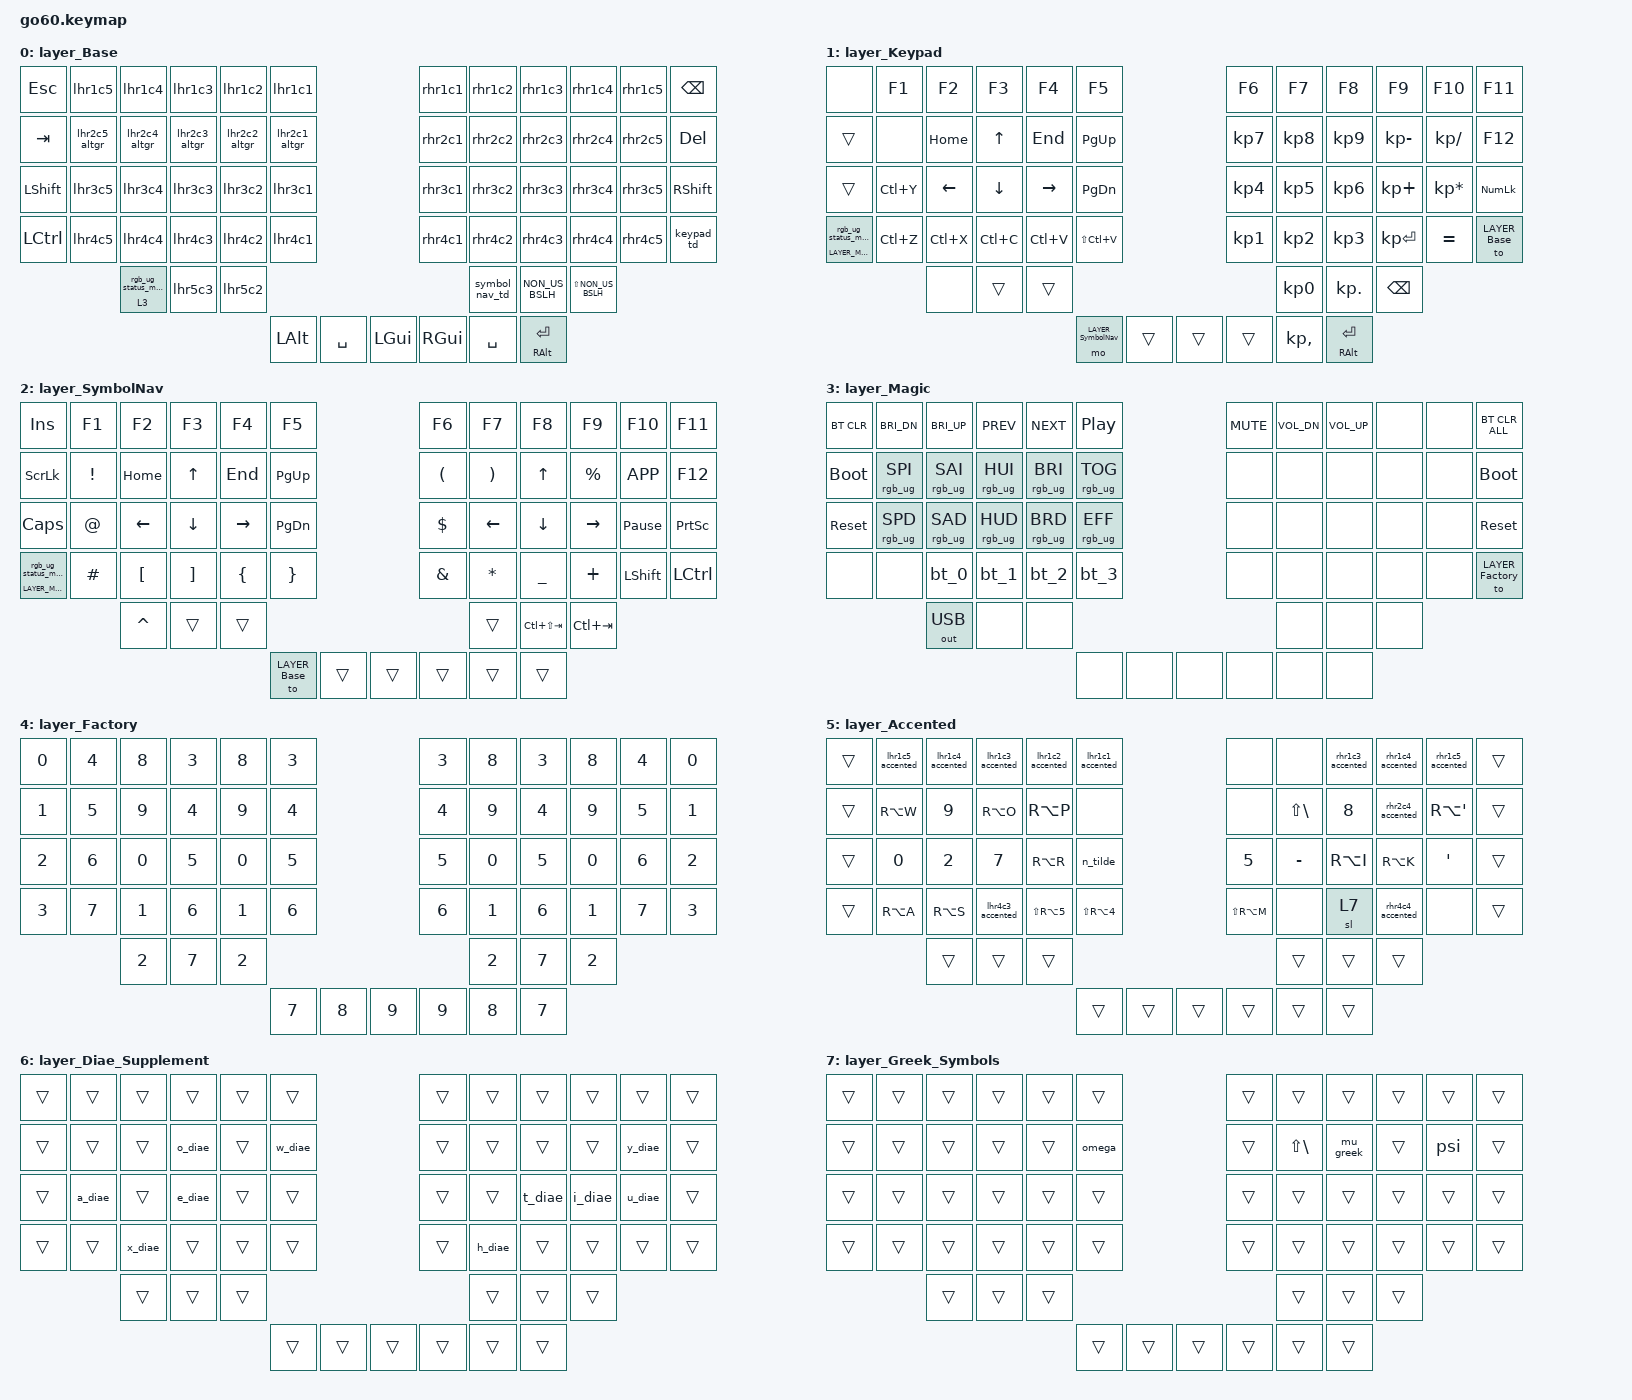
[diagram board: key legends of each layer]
/*
 * Copyright (c) 2020 The ZMK Contributors
 *
 * SPDX-License-Identifier: MIT
 */

#include <dt-bindings/zmk/input_transform.h>
#include <input/processors.dtsi>
#include <zephyr/dt-bindings/input/input-event-codes.h>
#include <behaviors.dtsi>
#include <dt-bindings/zmk/bt.h>
#include <dt-bindings/zmk/keys.h>
#include <dt-bindings/zmk/outputs.h>
#include <dt-bindings/zmk/rgb.h>

// layers

#define LAYER_Base 0
#define LAYER_Keypad 1
#define LAYER_SymbolNav 2
#define LAYER_Magic 3
#define LAYER_Factory 4

/ {
    input_processors {
        zip_click_to_right_click_mapper: zip_click_to_right_click_mapper {
            compatible = "zmk,input-processor-code-mapper";
            #input-processor-cells = <0>;
            type = <INPUT_EV_KEY>;
            map = <INPUT_BTN_0 INPUT_BTN_1>;
        };
    };

    behaviors {
        magic: magic {
            compatible = "zmk,behavior-hold-tap";
            #binding-cells = <2>;
            flavor = "tap-preferred";
            tapping-term-ms = <200>;
            bindings = <&mo>, <&rgb_ug_status_macro>;
        };

        keypad_td: keypad_td {
            compatible = "zmk,behavior-tap-dance";
            #binding-cells = <0>;
            tapping-term-ms = <200>;
            bindings = <&mo LAYER_Keypad>, <&to LAYER_Keypad>;
        };

        symbol_nav_td: symbol_nav_td {
            compatible = "zmk,behavior-tap-dance";
            #binding-cells = <0>;
            tapping-term-ms = <200>;
            bindings = <&mo LAYER_SymbolNav>, <&to LAYER_SymbolNav>;
        };

        bt_0: bt_0 {
            compatible = "zmk,behavior-tap-dance";
            #binding-cells = <0>;
            tapping-term-ms = <200>;
            bindings = <&bt_select_0>, <&bt BT_DISC 0>;
        };

        bt_1: bt_1 {
            compatible = "zmk,behavior-tap-dance";
            #binding-cells = <0>;
            tapping-term-ms = <200>;
            bindings = <&bt_select_1>, <&bt BT_DISC 1>;
        };

        bt_2: bt_2 {
            compatible = "zmk,behavior-tap-dance";
            #binding-cells = <0>;
            tapping-term-ms = <200>;
            bindings = <&bt_select_2>, <&bt BT_DISC 2>;
        };

        bt_3: bt_3 {
            compatible = "zmk,behavior-tap-dance";
            #binding-cells = <0>;
            tapping-term-ms = <200>;
            bindings = <&bt_select_3>, <&bt BT_DISC 3>;
        };


        /* ========================================================= *
         * MOD-MORPHS pour LH et RH R1 (touches 1-2-3-4-5-6-7-8-9-0) *
         * ========================================================= */

        /* =========
         * LH R1 C1 : 5 / % / ₅ / ⁵
         * ========= */

        lhr1c1_shift: lhr1c1_shift {
            compatible = "zmk,behavior-mod-morph";
            #binding-cells = <0>;
            mods = <(MOD_LSFT|MOD_RSFT)>;
            bindings = <&kp KP_N5 &kp LS(SQT)>;
        };

        lhr1c1_altgr_shift: lhr1c1_altgr_shift {
            compatible = "zmk,behavior-mod-morph";
            #binding-cells = <0>;
            mods = <(MOD_LSFT|MOD_RSFT)>;
            bindings = <&sub_5 &sup_5>;
        };

        lhr1c1: lhr1c1 {
            compatible = "zmk,behavior-mod-morph";
            #binding-cells = <0>;
            mods = <(MOD_RALT)>;
            bindings = <&lhr1c1_shift &lhr1c1_altgr_shift>;
        };

        /* =========
         * LH R1 C2 : 4 / $ / ₄ / ⁴
         * ========= */

        lhr1c2_shift: lhr1c2_shift {
            compatible = "zmk,behavior-mod-morph";
            #binding-cells = <0>;
            mods = <(MOD_LSFT|MOD_RSFT)>;
            bindings = <&kp KP_N4 &kp RBKT>;
        };

        lhr1c2_altgr_shift: lhr1c2_altgr_shift {
            compatible = "zmk,behavior-mod-morph";
            #binding-cells = <0>;
            mods = <(MOD_LSFT|MOD_RSFT)>;
            bindings = <&sub_4 &sup_4>;
        };

        lhr1c2: lhr1c2 {
            compatible = "zmk,behavior-mod-morph";
            #binding-cells = <0>;
            mods = <(MOD_RALT)>;
            bindings = <&lhr1c2_shift &lhr1c2_altgr_shift>;
        };

        /* =========
         * LH R1 C3 : 3 / » / ₃ / ³
         * ========= */

        lhr1c3_shift: lhr1c3_shift {
            compatible = "zmk,behavior-mod-morph";
            #binding-cells = <0>;
            mods = <(MOD_LSFT|MOD_RSFT)>;
            bindings = <&kp KP_N3 &kp RA(X)>;
        };

        lhr1c3_altgr_shift: lhr1c3_altgr_shift {
            compatible = "zmk,behavior-mod-morph";
            #binding-cells = <0>;
            mods = <(MOD_LSFT|MOD_RSFT)>;
            bindings = <&sub_3 &sup_3>;
        };

        lhr1c3: lhr1c3 {
            compatible = "zmk,behavior-mod-morph";
            #binding-cells = <0>;
            mods = <(MOD_RALT)>;
            bindings = <&lhr1c3_shift &lhr1c3_altgr_shift>;
        };

        /* =========
         * LH R1 C4 : 2 / « / ₂ / ²
         * ========= */

        lhr1c4_shift: lhr1c4_shift {
            compatible = "zmk,behavior-mod-morph";
            #binding-cells = <0>;
            mods = <(MOD_LSFT|MOD_RSFT)>;
            bindings = <&kp KP_N2 &kp RA(Z)>;
        };

        lhr1c4_altgr_shift: lhr1c4_altgr_shift {
            compatible = "zmk,behavior-mod-morph";
            #binding-cells = <0>;
            mods = <(MOD_LSFT|MOD_RSFT)>;
            bindings = <&sub_2 &sup_2>;
        };

        lhr1c4: lhr1c4 {
            compatible = "zmk,behavior-mod-morph";
            #binding-cells = <0>;
            mods = <(MOD_RALT)>;
            bindings = <&lhr1c4_shift &lhr1c4_altgr_shift>;
        };

        /* =========
         * LH R1 C5 : 1 / € / ₁ / ¹
         * ========= */

        lhr1c5_shift: lhr1c5_shift {
            compatible = "zmk,behavior-mod-morph";
            #binding-cells = <0>;
            mods = <(MOD_LSFT|MOD_RSFT)>;
            bindings = <&kp KP_N1 &kp RA(E)>;
        };

        lhr1c5_altgr_shift: lhr1c5_altgr_shift {
            compatible = "zmk,behavior-mod-morph";
            #binding-cells = <0>;
            mods = <(MOD_LSFT|MOD_RSFT)>;
            bindings = <&sub_1 &sup_1>;
        };

        lhr1c5: lhr1c5 {
            compatible = "zmk,behavior-mod-morph";
            #binding-cells = <0>;
            mods = <(MOD_RALT)>;
            bindings = <&lhr1c5_shift &lhr1c5_altgr_shift>;
        };

        /* =========
         * RH R1 C1 : 6 / ^ / ₆ / ⁶
         * ========= */
        
        rhr1c1_shift: rhr1c1_shift {
            compatible = "zmk,behavior-mod-morph";
            #binding-cells = <0>;
            mods = <(MOD_LSFT|MOD_RSFT)>;
            bindings = <&kp KP_N6 &kp LBKT>;       // ^ = LBKT en FR
        };
        
        rhr1c1_altgr_shift: rhr1c1_altgr_shift {
            compatible = "zmk,behavior-mod-morph";
            #binding-cells = <0>;
            mods = <(MOD_LSFT|MOD_RSFT)>;
            bindings = <&sub_6 &sup_6>;
        };
        
        rhr1c1: rhr1c1 {
            compatible = "zmk,behavior-mod-morph";
            #binding-cells = <0>;
            mods = <(MOD_RALT)>;
            bindings = <&rhr1c1_shift &rhr1c1_altgr_shift>;
        };
        
        /* =========
         * RH R1 C2 : 7 / & / ₇ / ⁷
         * ========= */
        
        rhr1c2_shift: rhr1c2_shift {
            compatible = "zmk,behavior-mod-morph";
            #binding-cells = <0>;
            mods = <(MOD_LSFT|MOD_RSFT)>;
            bindings = <&kp KP_N7 &kp N1>;         // & = N1 en FR
        };
        
        rhr1c2_altgr_shift: rhr1c2_altgr_shift {
            compatible = "zmk,behavior-mod-morph";
            #binding-cells = <0>;
            mods = <(MOD_LSFT|MOD_RSFT)>;
            bindings = <&sub_7 &sup_7>;
        };
        
        rhr1c2: rhr1c2 {
            compatible = "zmk,behavior-mod-morph";
            #binding-cells = <0>;
            mods = <(MOD_RALT)>;
            bindings = <&rhr1c2_shift &rhr1c2_altgr_shift>;
        };
        
        /* =========
         * RH R1 C3 : 8 / * / ₈ / ⁸
         * ========= */
        
        rhr1c3_shift: rhr1c3_shift {
            compatible = "zmk,behavior-mod-morph";
            #binding-cells = <0>;
            mods = <(MOD_LSFT|MOD_RSFT)>;
            bindings = <&kp KP_N8 &kp BSLH>;       // * = BSLH en FR
        };
        
        rhr1c3_altgr_shift: rhr1c3_altgr_shift {
            compatible = "zmk,behavior-mod-morph";
            #binding-cells = <0>;
            mods = <(MOD_LSFT|MOD_RSFT)>;
            bindings = <&sub_8 &sup_8>;
        };
        
        rhr1c3: rhr1c3 {
            compatible = "zmk,behavior-mod-morph";
            #binding-cells = <0>;
            mods = <(MOD_RALT)>;
            bindings = <&rhr1c3_shift &rhr1c3_altgr_shift>;
        };
        
        /* =========
         * RH R1 C4 : 9 / # / ₉ / ⁹
         * ========= */
        
        rhr1c4_shift: rhr1c4_shift {
            compatible = "zmk,behavior-mod-morph";
            #binding-cells = <0>;
            mods = <(MOD_LSFT|MOD_RSFT)>;
            bindings = <&kp KP_N9 &kp RA(N3)>;     // # = AltGr+3 en FR
        };
        
        rhr1c4_altgr_shift: rhr1c4_altgr_shift {
            compatible = "zmk,behavior-mod-morph";
            #binding-cells = <0>;
            mods = <(MOD_LSFT|MOD_RSFT)>;
            bindings = <&sub_9 &sup_9>;
        };
        
        rhr1c4: rhr1c4 {
            compatible = "zmk,behavior-mod-morph";
            #binding-cells = <0>;
            mods = <(MOD_RALT)>;
            bindings = <&rhr1c4_shift &rhr1c4_altgr_shift>;
        };
        
        /* =========
         * RH R1 C5 : 0 / @ / ₀ / ⁰
         * ========= */
        
        rhr1c5_shift: rhr1c5_shift {
            compatible = "zmk,behavior-mod-morph";
            #binding-cells = <0>;
            mods = <(MOD_LSFT|MOD_RSFT)>;
            bindings = <&kp KP_N0 &kp RA(N0)>;     // @ = AltGr+0 en FR
        };
        
        rhr1c5_altgr_shift: rhr1c5_altgr_shift {
            compatible = "zmk,behavior-mod-morph";
            #binding-cells = <0>;
            mods = <(MOD_LSFT|MOD_RSFT)>;
            bindings = <&sub_0 &sup_0>;
        };
        
        rhr1c5: rhr1c5 {
            compatible = "zmk,behavior-mod-morph";
            #binding-cells = <0>;
            mods = <(MOD_RALT)>;
            bindings = <&rhr1c5_shift &rhr1c5_altgr_shift>;
        };

        /* ========================================================= *
         * MOD-MORPHS pour LH et RH R2 (touches q-c-o-p-w-j-m-d-*-y) *
         * ========================================================= */

        /* =========
         * LH R2 C5 : q / Q / ^ / none
         * ========= */
        
        // NIVEAU 1 : Détecte AltGr
        lhr2c5_altgr: lhr2c5_altgr {
            compatible = "zmk,behavior-mod-morph";
            #binding-cells = <0>;
            mods = <(MOD_RALT)>;
            bindings = <&kp A &lhr2c5_shift_altgr>;
        };
        
        // NIVEAU 2 : Avec AltGr (détecte Shift)
        lhr2c5_shift_altgr: lhr2c5_shift_altgr {
            compatible = "zmk,behavior-mod-morph";
            #binding-cells = <0>;
            mods = <(MOD_LSFT|MOD_RSFT)>;
            bindings = <&kp RA(N9) &none>;    // AltGr = ^, Shift+AltGr = RIEN
        };

        /* =========
         * LH R2 C4 : c / C / < / ≤
         * ========= */

        lhr2c4_altgr_shift: lhr2c4_altgr_shift {
            compatible = "zmk,behavior-mod-morph";
            #binding-cells = <0>;
            mods = <(MOD_LSFT|MOD_RSFT)>;
            bindings = <&kp NON_US_BSLH &kp RA(NON_US_BSLH)>;
        };

        lhr2c4_altgr: lhr2c4_altgr {
            compatible = "zmk,behavior-mod-morph";
            #binding-cells = <0>;
            mods = <(MOD_RALT)>;
            bindings = <&kp C &lhr2c4_altgr_shift>;
        };

        /* =========
         * LH R2 C3 : o / O / > / ≥
         * ========= */

        lhr2c3_altgr_shift: lhr2c3_altgr_shift {
            compatible = "zmk,behavior-mod-morph";
            #binding-cells = <0>;
            mods = <(MOD_LSFT|MOD_RSFT)>;
            bindings = <&kp LS(NON_US_BSLH) &kp LS(RA(NON_US_BSLH))>;
        };

        lhr2c3_altgr: lhr2c3_altgr {
            compatible = "zmk,behavior-mod-morph";
            #binding-cells = <0>;
            mods = <(MOD_RALT)>;
            bindings = <&kp O &lhr2c3_altgr_shift>;
        };

        /* =========
         * LH R2 C2 : p / P / $ / none
         * ========= */

        lhr2c2_altgr: lhr2c2_altgr {
            compatible = "zmk,behavior-mod-morph";
            #binding-cells = <0>;
            mods = <(MOD_RALT)>;
            bindings = <&kp P &lhr2c2_shift_altgr>;
        };

        lhr2c2_shift_altgr: lhr2c2_shift_altgr {
            compatible = "zmk,behavior-mod-morph";
            #binding-cells = <0>;
            mods = <(MOD_LSFT|MOD_RSFT)>;
            bindings = <&kp RBKT  &none>;    // AltGr = $, Shift+AltGr = RIEN
        };
    
        /* =========
         * LH R2 C1 : w / W / % / ‰
         * ========= */

        lhr2c1_altgr: lhr2c1_altgr {
            compatible = "zmk,behavior-mod-morph";
            #binding-cells = <0>;
            mods = <(MOD_RALT)>;
            bindings = <&kp Z &lhr2c1_altgr_shift>;
        };

        lhr2c1_altgr_shift: lhr2c1_altgr_shift {
            compatible = "zmk,behavior-mod-morph";
            #binding-cells = <0>;
            mods = <(MOD_LSFT|MOD_RSFT)>;
            bindings = <&kp LS(SQT) &permille_compose>;
        };

        /* =========
         * RH R2 C1 : j / J / @ / rien
         * ========= */
        
        rhr2c1: rhr2c1 {
            compatible = "zmk,behavior-mod-morph";
            #binding-cells = <0>;
            mods = <(MOD_RALT)>;
            bindings = <&kp J &rhr2c1_shift_altgr>;
        };
        
        rhr2c1_shift_altgr: rhr2c1_shift_altgr {
            compatible = "zmk,behavior-mod-morph";
            #binding-cells = <0>;
            mods = <(MOD_LSFT|MOD_RSFT)>;
            bindings = <&kp RA(N0) &none>;       // @ = AltGr+0 en FR, Shift+AltGr = rien
        };
        
        /* =========
         * RH R2 C2 : m / M / & / rien
         * ========= */
        
        rhr2c2: rhr2c2 {
            compatible = "zmk,behavior-mod-morph";
            #binding-cells = <0>;
            mods = <(MOD_RALT)>;
            bindings = <&kp SEMICOLON &rhr2c2_shift_altgr>;  // M en mapping inversé = SEMICOLON
        };
        
        rhr2c2_shift_altgr: rhr2c2_shift_altgr {
            compatible = "zmk,behavior-mod-morph";
            #binding-cells = <0>;
            mods = <(MOD_LSFT|MOD_RSFT)>;
            bindings = <&kp N1 &none>;           // & = N1 en FR, Shift+AltGr = rien
        };
        
        /* =========
         * RH R2 C3 : d / D / * / ×
         * ========= */
        
        rhr2c3: rhr2c3 {
            compatible = "zmk,behavior-mod-morph";
            #binding-cells = <0>;
            mods = <(MOD_RALT)>;
            bindings = <&kp D &rhr2c3_shift_altgr>;
        };
        
        rhr2c3_shift_altgr: rhr2c3_shift_altgr {
            compatible = "zmk,behavior-mod-morph";
            #binding-cells = <0>;
            mods = <(MOD_LSFT|MOD_RSFT)>;
            bindings = <&kp BSLH &kp RA(COMMA)>;  // * = BSLH, × = AltGr+; (COMMA en FR)
        };
        
        /* =========
         * RH R2 C4 : layer_accented / ! / ' / rien
         * ========= */
        
        rhr2c4: rhr2c4 {
            compatible = "zmk,behavior-mod-morph";
            #binding-cells = <0>;
            mods = <(MOD_RALT)>;
            bindings = <&rhr2c4_no_altgr &rhr2c4_shift_altgr>;
        };
        
        rhr2c4_no_altgr: rhr2c4_no_altgr {
            compatible = "zmk,behavior-mod-morph";
            #binding-cells = <0>;
            mods = <(MOD_LSFT|MOD_RSFT)>;
            bindings = <&sl 5 &kp FSLH>;   // layer accents / ! (Shift+SLASH en FR)
        };
        
        rhr2c4_shift_altgr: rhr2c4_shift_altgr {
            compatible = "zmk,behavior-mod-morph";
            #binding-cells = <0>;
            mods = <(MOD_LSFT|MOD_RSFT)>;
            bindings = <&kp N4 &none>;              // ' = N4 en FR, Shift+AltGr = rien
        };
        
        /* =========
         * RH R2 C5 : y / Y / ` / rien
         * ========= */
        
        rhr2c5: rhr2c5 {
            compatible = "zmk,behavior-mod-morph";
            #binding-cells = <0>;
            mods = <(MOD_RALT)>;
            bindings = <&kp Y &rhr2c5_shift_altgr>;
        };
        
        rhr2c5_shift_altgr: rhr2c5_shift_altgr {
            compatible = "zmk,behavior-mod-morph";
            #binding-cells = <0>;
            mods = <(MOD_LSFT|MOD_RSFT)>;
            bindings = <&kp RA(N7) &none>;            // ` = AltGr+7 en FR, Shift+AltGr = rien
        };


        /* ========================================================= *
         * MOD-MORPHS pour LH et RH R3 (touches a-s-e-n-f-l-r-t-i-u  *
         * ========================================================= */

        /* ==========================================
         * MOD-MORPHS pour LH R3
         * ========================================== */
        
        /* =========
         * LH R3 C1 : f / F / = / ≠
         * ========= */
        
        lhr3c1: lhr3c1 {
            compatible = "zmk,behavior-mod-morph";
            #binding-cells = <0>;
            mods = <(MOD_RALT)>;
            bindings = <&kp F &lhr3c1_shift_altgr>;
        };
        
        lhr3c1_shift_altgr: lhr3c1_shift_altgr {
            compatible = "zmk,behavior-mod-morph";
            #binding-cells = <0>;
            mods = <(MOD_LSFT|MOD_RSFT)>;
            bindings = <&kp EQUAL &kp LS(RA(MINUS))>;   // = / ≠
        };
        
        /* =========
         * LH R3 C2 : n / N / } / rien
         * ========= */
        
        lhr3c2: lhr3c2 {
            compatible = "zmk,behavior-mod-morph";
            #binding-cells = <0>;
            mods = <(MOD_RALT)>;
            bindings = <&kp N &lhr3c2_shift_altgr>;
        };
        
        lhr3c2_shift_altgr: lhr3c2_shift_altgr {
            compatible = "zmk,behavior-mod-morph";
            #binding-cells = <0>;
            mods = <(MOD_LSFT|MOD_RSFT)>;
            bindings = <&kp RA(EQUAL) &none>;           // } / rien
        };
        
        /* =========
         * LH R3 C3 : e / E / ) / rien
         * ========= */
        
        lhr3c3: lhr3c3 {
            compatible = "zmk,behavior-mod-morph";
            #binding-cells = <0>;
            mods = <(MOD_RALT)>;
            bindings = <&kp E &lhr3c3_shift_altgr>;
        };
        
        lhr3c3_shift_altgr: lhr3c3_shift_altgr {
            compatible = "zmk,behavior-mod-morph";
            #binding-cells = <0>;
            mods = <(MOD_LSFT|MOD_RSFT)>;
            bindings = <&kp MINUS &none>;               // ) / rien
        };
        
        /* =========
         * LH R3 C4 : s / S / ( / rien
         * ========= */
        
        lhr3c4: lhr3c4 {
            compatible = "zmk,behavior-mod-morph";
            #binding-cells = <0>;
            mods = <(MOD_RALT)>;
            bindings = <&kp S &lhr3c4_shift_altgr>;
        };
        
        lhr3c4_shift_altgr: lhr3c4_shift_altgr {
            compatible = "zmk,behavior-mod-morph";
            #binding-cells = <0>;
            mods = <(MOD_LSFT|MOD_RSFT)>;
            bindings = <&kp N5 &none>;                  // ( / rien
        };
        
        /* =========
         * LH R3 C5 : a / A / { / rien
         * ========= */
        
        lhr3c5: lhr3c5 {
            compatible = "zmk,behavior-mod-morph";
            #binding-cells = <0>;
            mods = <(MOD_RALT)>;
            bindings = <&kp Q &lhr3c5_shift_altgr>;     // A en mapping inversé = Q
        };
        
        lhr3c5_shift_altgr: lhr3c5_shift_altgr {
            compatible = "zmk,behavior-mod-morph";
            #binding-cells = <0>;
            mods = <(MOD_LSFT|MOD_RSFT)>;
            bindings = <&kp RA(N4) &none>;              // { / rien
        };
        
        /* ==========================================
         * MOD-MORPHS pour RH R3
         * ========================================== */
        
        /* =========
         * RH R3 C1 : l / L / \ / rien
         * ========= */
        
        rhr3c1: rhr3c1 {
            compatible = "zmk,behavior-mod-morph";
            #binding-cells = <0>;
            mods = <(MOD_RALT)>;
            bindings = <&kp L &rhr3c1_shift_altgr>;
        };
        
        rhr3c1_shift_altgr: rhr3c1_shift_altgr {
            compatible = "zmk,behavior-mod-morph";
            #binding-cells = <0>;
            mods = <(MOD_LSFT|MOD_RSFT)>;
            bindings = <&kp RA(N8) &none>;              // \ / rien
        };
        
        /* =========
         * RH R3 C2 : r / R / + / ±
         * ========= */
        
        rhr3c2: rhr3c2 {
            compatible = "zmk,behavior-mod-morph";
            #binding-cells = <0>;
            mods = <(MOD_RALT)>;
            bindings = <&kp R &rhr3c2_shift_altgr>;
        };
        
        rhr3c2_shift_altgr: rhr3c2_shift_altgr {
            compatible = "zmk,behavior-mod-morph";
            #binding-cells = <0>;
            mods = <(MOD_LSFT|MOD_RSFT)>;
            bindings = <&kp LS(EQUAL) &kp LS(RA(EQUAL))>;  // + / ±
        };
        
        /* =========
         * RH R3 C3 : t / T / - / rien
         * ========= */
        
        rhr3c3: rhr3c3 {
            compatible = "zmk,behavior-mod-morph";
            #binding-cells = <0>;
            mods = <(MOD_RALT)>;
            bindings = <&kp T &rhr3c3_shift_altgr>;
        };
        
        rhr3c3_shift_altgr: rhr3c3_shift_altgr {
            compatible = "zmk,behavior-mod-morph";
            #binding-cells = <0>;
            mods = <(MOD_LSFT|MOD_RSFT)>;
            bindings = <&kp N6 &none>;                  // - / rien
        };
        
        /* =========
         * RH R3 C4 : i / I / / / ÷
         * ========= */
        
        rhr3c4: rhr3c4 {
            compatible = "zmk,behavior-mod-morph";
            #binding-cells = <0>;
            mods = <(MOD_RALT)>;
            bindings = <&kp I &rhr3c4_shift_altgr>;
        };
        
        rhr3c4_shift_altgr: rhr3c4_shift_altgr {
            compatible = "zmk,behavior-mod-morph";
            #binding-cells = <0>;
            mods = <(MOD_LSFT|MOD_RSFT)>;
            bindings = <&kp LS(DOT) &kp RA(DOT)>;       // / / ÷
        };
        
        /* =========
         * RH R3 C5 : u / U / " / rien
         * ========= */
        
        rhr3c5: rhr3c5 {
            compatible = "zmk,behavior-mod-morph";
            #binding-cells = <0>;
            mods = <(MOD_RALT)>;
            bindings = <&kp U &rhr3c5_shift_altgr>;
        };
        
        rhr3c5_shift_altgr: rhr3c5_shift_altgr {
            compatible = "zmk,behavior-mod-morph";
            #binding-cells = <0>;
            mods = <(MOD_LSFT|MOD_RSFT)>;
            bindings = <&kp N3 &none>;                  // " / rien
        };

        /* ========================================================= *
         * MOD-MORPHS pour LH et RH R4 (touches z-x---v-b-.-h-g-.-k  *
         * ========================================================= */
        
        /* ==========================================
         * MOD-MORPHS pour LH R4
         * ========================================== */
        
        /* =========
         * LH R4 C1 : b / B / # / rien
         * ========= */
        
        lhr4c1: lhr4c1 {
            compatible = "zmk,behavior-mod-morph";
            #binding-cells = <0>;
            mods = <(MOD_RALT)>;
            bindings = <&kp B &lhr4c1_shift_altgr>;
        };
        
        lhr4c1_shift_altgr: lhr4c1_shift_altgr {
            compatible = "zmk,behavior-mod-morph";
            #binding-cells = <0>;
            mods = <(MOD_LSFT|MOD_RSFT)>;
            bindings = <&kp RA(N3) &none>;             // # / rien
        };
        
        /* =========
         * LH R4 C2 : v / V / _ / –
         * ========= */
        
        lhr4c2: lhr4c2 {
            compatible = "zmk,behavior-mod-morph";
            #binding-cells = <0>;
            mods = <(MOD_RALT)>;
            bindings = <&kp V &lhr4c2_shift_altgr>;
        };
        
        lhr4c2_shift_altgr: lhr4c2_shift_altgr {
            compatible = "zmk,behavior-mod-morph";
            #binding-cells = <0>;
            mods = <(MOD_LSFT|MOD_RSFT)>;
            bindings = <&kp N8 &kp LS(RA(N5))>;        // _ / –
        };
        
        /* =========
         * LH R4 C3 : - / ? / ] / rien
         * ========= */
        
        lhr4c3: lhr4c3 {
            compatible = "zmk,behavior-mod-morph";
            #binding-cells = <0>;
            mods = <(MOD_RALT)>;
            bindings = <&lhr4c3_no_altgr &lhr4c3_shift_altgr>;
        };
        
        lhr4c3_no_altgr: lhr4c3_no_altgr {
            compatible = "zmk,behavior-mod-morph";
            #binding-cells = <0>;
            mods = <(MOD_LSFT|MOD_RSFT)>;
            bindings = <&kp N6 &kp LS(M)>;             // - / ?
        };
        
        lhr4c3_shift_altgr: lhr4c3_shift_altgr {
            compatible = "zmk,behavior-mod-morph";
            #binding-cells = <0>;
            mods = <(MOD_LSFT|MOD_RSFT)>;
            bindings = <&kp RA(MINUS) &none>;          // ] / rien
        };
        
        /* =========
         * LH R4 C4 : x / X / [ / rien
         * ========= */
        
        lhr4c4: lhr4c4 {
            compatible = "zmk,behavior-mod-morph";
            #binding-cells = <0>;
            mods = <(MOD_RALT)>;
            bindings = <&kp X &lhr4c4_shift_altgr>;
        };
        
        lhr4c4_shift_altgr: lhr4c4_shift_altgr {
            compatible = "zmk,behavior-mod-morph";
            #binding-cells = <0>;
            mods = <(MOD_LSFT|MOD_RSFT)>;
            bindings = <&kp RA(N5) &none>;             // [ / rien
        };
        
        /* =========
         * LH R4 C5 : z / Z / ~ / rien
         * ========= */
        
        lhr4c5: lhr4c5 {
            compatible = "zmk,behavior-mod-morph";
            #binding-cells = <0>;
            mods = <(MOD_RALT)>;
            bindings = <&kp W &lhr4c5_shift_altgr>;    // Z en mapping inversé = W
        };
        
        lhr4c5_shift_altgr: lhr4c5_shift_altgr {
            compatible = "zmk,behavior-mod-morph";
            #binding-cells = <0>;
            mods = <(MOD_LSFT|MOD_RSFT)>;
            bindings = <&kp RA(N2) &none>;             // ~ / rien
        };
        
        /* ==========================================
         * MOD-MORPHS pour RH R4
         * ========================================== */
        
        /* =========
         * RH R4 C1 : . / : / | / ¦
         * ========= */
        
        rhr4c1: rhr4c1 {
            compatible = "zmk,behavior-mod-morph";
            #binding-cells = <0>;
            mods = <(MOD_RALT)>;
            bindings = <&rhr4c1_no_altgr &rhr4c1_shift_altgr>;
        };
        
        rhr4c1_no_altgr: rhr4c1_no_altgr {
            compatible = "zmk,behavior-mod-morph";
            #binding-cells = <0>;
            mods = <(MOD_LSFT|MOD_RSFT)>;
            bindings = <&kp LS(COMMA) &kp DOT>;        // . / :
        };
        
        rhr4c1_shift_altgr: rhr4c1_shift_altgr {
            compatible = "zmk,behavior-mod-morph";
            #binding-cells = <0>;
            mods = <(MOD_LSFT|MOD_RSFT)>;
            bindings = <&kp RA(N6) &broken_bar_compose>;  // | / ¦
        };
        
        /* =========
         * RH R4 C2 : h / H / ! / ¬
         * ========= */
        
        rhr4c2: rhr4c2 {
            compatible = "zmk,behavior-mod-morph";
            #binding-cells = <0>;
            mods = <(MOD_RALT)>;
            bindings = <&kp H &rhr4c2_shift_altgr>;
        };
        
        rhr4c2_shift_altgr: rhr4c2_shift_altgr {
            compatible = "zmk,behavior-mod-morph";
            #binding-cells = <0>;
            mods = <(MOD_LSFT|MOD_RSFT)>;
            bindings = <&kp FSLH &kp RA(N)>;           // ! / ¬
        };
        
        /* =========
         * RH R4 C3 : g / G / ; / rien
         * ========= */
        
        rhr4c3: rhr4c3 {
            compatible = "zmk,behavior-mod-morph";
            #binding-cells = <0>;
            mods = <(MOD_RALT)>;
            bindings = <&kp G &rhr4c3_shift_altgr>;
        };
        
        rhr4c3_shift_altgr: rhr4c3_shift_altgr {
            compatible = "zmk,behavior-mod-morph";
            #binding-cells = <0>;
            mods = <(MOD_LSFT|MOD_RSFT)>;
            bindings = <&kp COMMA &none>;              // ; / rien
        };
        
        /* =========
         * RH R4 C4 : , / ; / : / rien
         * ========= */
        
        rhr4c4: rhr4c4 {
            compatible = "zmk,behavior-mod-morph";
            #binding-cells = <0>;
            mods = <(MOD_RALT)>;
            bindings = <&rhr4c4_no_altgr &rhr4c4_shift_altgr>;
        };
        
        rhr4c4_no_altgr: rhr4c4_no_altgr {
            compatible = "zmk,behavior-mod-morph";
            #binding-cells = <0>;
            mods = <(MOD_LSFT|MOD_RSFT)>;
            bindings = <&kp M &kp COMMA>;              // , / ;
        };
        
        rhr4c4_shift_altgr: rhr4c4_shift_altgr {
            compatible = "zmk,behavior-mod-morph";
            #binding-cells = <0>;
            mods = <(MOD_LSFT|MOD_RSFT)>;
            bindings = <&kp DOT &none>;                // : / rien
        };
        
        /* =========
         * RH R4 C5 : k / K / ? / rien
         * ========= */
        
        rhr4c5: rhr4c5 {
            compatible = "zmk,behavior-mod-morph";
            #binding-cells = <0>;
            mods = <(MOD_RALT)>;
            bindings = <&kp K &rhr4c5_shift_altgr>;
        };
        
        rhr4c5_shift_altgr: rhr4c5_shift_altgr {
            compatible = "zmk,behavior-mod-morph";
            #binding-cells = <0>;
            mods = <(MOD_LSFT|MOD_RSFT)>;
            bindings = <&kp LS(M) &none>;              // ? / rien
        };


        /* ========================================================= *
         * LH R5 C3 et C2 (parenthèses/crochets/acc) *
         * ========================================================= */

        /* =========
         * LH R5 C3 : ( / [ / {
         * ========= */

        lhr5c3: lhr5c3 {
            compatible = "zmk,behavior-mod-morph";
            #binding-cells = <0>;
            mods = <(MOD_RALT)>;
            bindings = <&lhr5c3_no_altgr &lhr5c3_altgr>;
        };

        lhr5c3_no_altgr: lhr5c3_no_altgr {
            compatible = "zmk,behavior-mod-morph";
            #binding-cells = <0>;
            mods = <(MOD_LSFT|MOD_RSFT)>;
            bindings = <&kp N5 &kp RA(N5)>;              // ( ou [
        };

        lhr5c3_altgr: lhr5c3_altgr {
            compatible = "zmk,behavior-mod-morph";
            #binding-cells = <0>;
            mods = <(MOD_LSFT|MOD_RSFT)>;
            bindings = <&kp RA(N4) &none>;          // { / {
        };


        /* =========
         * LH R5 C2 : ) / ] / }
         * ========= */

        lhr5c2: lhr5c2 {
            compatible = "zmk,behavior-mod-morph";
            #binding-cells = <0>;
            mods = <(MOD_RALT)>;
            bindings = <&lhr5c2_no_altgr &lhr5c2_altgr>;
        };

        lhr5c2_no_altgr: lhr5c2_no_altgr {
            compatible = "zmk,behavior-mod-morph";
            #binding-cells = <0>;
            mods = <(MOD_LSFT|MOD_RSFT)>;
            bindings = <&kp MINUS &kp RA(MINUS)>;        // ) / ]
        };

        lhr5c2_altgr: lhr5c2_altgr {
            compatible = "zmk,behavior-mod-morph";
            #binding-cells = <0>;
            mods = <(MOD_LSFT|MOD_RSFT)>;
            bindings = <&kp RA(EQUAL) &none>;    // } / }

        };

        /* ========================================================= *
         * je pense que les 5 fonctions suivantes sont inutiles                                     *
         * ========================================================= */

        minus_qmark: minus_qmark {
            compatible = "zmk,behavior-mod-morph";
            label = "- / ?";
            bindings = <&kp KP_MINUS>, <&kp QMARK>;

            #binding-cells = <0>;
            mods = <(MOD_LSFT|MOD_RSFT)>;
        };

        dot_colon: dot_colon {
            compatible = "zmk,behavior-mod-morph";
            label = ". / :";
            bindings = <&kp KP_DOT>, <&kp COLON>;

            #binding-cells = <0>;
            mods = <(MOD_LSFT|MOD_RSFT)>;
        };

        comma_semi: comma_semi {
            compatible = "zmk,behavior-mod-morph";
            label = ", / ;";
            bindings = <&kp KP_COMMA>, <&kp SEMI>;

            #binding-cells = <0>;
            mods = <(MOD_LSFT|MOD_RSFT)>;
        };

        q_or_circ: q_or_circ {
            compatible = "zmk,behavior-mod-morph";
            label = "q / ^";
            bindings = <&kp A>, <&kp LBKT>;

            #binding-cells = <0>;
            mods = <(MOD_RALT)>;
        };

        td_accent_layer: td_accent_layer {
            compatible = "zmk,behavior-tap-dance";
            label = "Layer 5/6";
            #binding-cells = <0>;
            bindings = <&sl 5>, <&sl 6>;

            tapping-term-ms = <400>;
        };

        /* ========================================================= *
         * Layer_accented pour LH et RH R1                           *
         * ========================================================= */
        
         /* ==================*
          * LH R1 C5 : „ et , *
          * ================= */

        lhr1c5_accented: lhr1c5_accented {
            compatible = "zmk,behavior-mod-morph";
            #binding-cells = <0>;
            mods = <(MOD_LSFT|MOD_RSFT)>;
            bindings = <&kp LS(RA(S)) &kp M>;  // „ / ‚
        };

        /* ==================*
         * LH R1 C4 : " / '  *
         * ================= */

        lhr1c4_accented: lhr1c4_accented {
            compatible = "zmk,behavior-mod-morph";
            #binding-cells = <0>;
            mods = <(MOD_LSFT|MOD_RSFT)>;
            bindings = <&kp LS(RA(Z)) &kp RA(F)>;  // " / '
        };

        /* ==================*
         * LH R1 C3 : " / '  *
         * ================= */

        lhr1c3_accented: lhr1c3_accented {
            compatible = "zmk,behavior-mod-morph";
            #binding-cells = <0>;
            mods = <(MOD_LSFT|MOD_RSFT)>;
            bindings = <&kp LS(RA(X)) &kp RA(G)>;  // " / '
        };

        /* ==================*
         * LH R1 C2 : ¢      *
         * ================= */

        lhr1c2_accented: lhr1c2_accented {
            compatible = "zmk,behavior-mod-morph";
            #binding-cells = <0>;
            mods = <(MOD_LSFT|MOD_RSFT)>;
            bindings = <&kp LS(RA(E)) &none>;  // ¢ / none
        };

        /* ==================*
         * LH R1 C1 : ‰      *
         * ================= */

        lhr1c1_accented: lhr1c1_accented {
            compatible = "zmk,behavior-mod-morph";
            #binding-cells = <0>;
            mods = <(MOD_LSFT|MOD_RSFT)>;
            bindings = <&permille_compose &none>;  // ‰ / none
        };

        /* ==================*
         * RH R1 C3 : §      *
         * ================= */

        rhr1c3_accented: rhr1c3_accented {
            compatible = "zmk,behavior-mod-morph";
            #binding-cells = <0>;
            mods = <(MOD_LSFT|MOD_RSFT)>;
            bindings = <&kp LS(FSLH) &none>;  // § / none
        };

        /* ==================*
         * RH R1 C4 : ¶      *
         * ================= */

        rhr1c4_accented: rhr1c4_accented {
            compatible = "zmk,behavior-mod-morph";
            #binding-cells = <0>;
            mods = <(MOD_LSFT|MOD_RSFT)>;
            bindings = <&pilcrow_compose &none>;  // ¶ / none
        };

        /* ==================*
         * RH R1 C5 : °      *
         * ================= */

        rhr1c5_accented: rhr1c5_accented {
            compatible = "zmk,behavior-mod-morph";
            #binding-cells = <0>;
            mods = <(MOD_LSFT|MOD_RSFT)>;
            bindings = <&kp LS(MINUS) &none>;  // ° / none
        };

        /* ========================================================= *
         * Layer_accented pour LH et RH R2                           *
         * ========================================================= */

        /* ====================*
         * RH R2 C4 : Dia / ¡  *
         * =================== */

        rhr2c4_accented: rhr2c4_accented {
            compatible = "zmk,behavior-mod-morph";
            #binding-cells = <0>;
            mods = <(MOD_LSFT|MOD_RSFT)>;
            bindings = <&sl 6 &kp RA(FSLH)>;  // layer_diaeresis / ¡
        };

        /* ========================================================= *
         * Layer_accented pour LH et RH R4                           *
         * ========================================================= */

        /* ====================*
         * LH R4 C3 : - / ¿    *
         * =================== */

        lhr4c3_accented: lhr4c3_accented {
            compatible = "zmk,behavior-mod-morph";
            #binding-cells = <0>;
            mods = <(MOD_LSFT|MOD_RSFT)>;
            bindings = <&kp N6 &kp RA(M)>;  // - / ¿
        };

        /* ====================*
         * RH R4 C4 : · / •    *
         * =================== */

        rhr4c4_accented: rhr4c4_accented {
            compatible = "zmk,behavior-mod-morph";
            #binding-cells = <0>;
            mods = <(MOD_LSFT|MOD_RSFT)>;
            bindings = <&kp LS(RA(COMMA)) &bullet_compose>;  // · / •
        };

    };

    macros {
        rgb_ug_status_macro: rgb_ug_status_macro {
            compatible = "zmk,behavior-macro";
            #binding-cells = <0>;
            bindings = <&rgb_ug RGB_STATUS>;
        };

        bt_select_0: bt_select_0 {
            compatible = "zmk,behavior-macro";
            #binding-cells = <0>;
            bindings = <&out OUT_BLE &bt BT_SEL 0>;
        };

        bt_select_1: bt_select_1 {
            compatible = "zmk,behavior-macro";
            #binding-cells = <0>;
            bindings = <&out OUT_BLE &bt BT_SEL 1>;
        };

        bt_select_2: bt_select_2 {
            compatible = "zmk,behavior-macro";
            #binding-cells = <0>;
            bindings = <&out OUT_BLE &bt BT_SEL 2>;
        };

        bt_select_3: bt_select_3 {
            compatible = "zmk,behavior-macro";
            #binding-cells = <0>;
            bindings = <&out OUT_BLE &bt BT_SEL 3>;
        };

         /* ==========================================
         * MACROS pour R4
         * ========================================== */
        
        // ¦ (broken bar) U+00A6 - Compose : Compose + ! + ^
        broken_bar_compose: broken_bar_compose {
            compatible = "zmk,behavior-macro";
            #binding-cells = <0>;
            wait-ms = <40>;
            tap-ms = <40>;
            bindings =
                <&macro_release &kp RALT>,
                <&macro_release &kp LSHFT>,
                <&macro_release &kp RSHFT>,
                <&macro_tap>, <&kp RCTRL>,         /* Compose */
                <&macro_tap>, <&kp FSLH>,          /* ! en FR */
                <&macro_tap>, <&kp RA(N9)>;        /* ^ en FR */
            label = "¦";
        };

        

        /* ======================================================= *
         * MACROS pour INDICES et EXPOSANTS de 1-2-3-4-5-6-7-8-9-0 *
         * ======================================================= */

        /* Subscripts: Compose + _ + digit => ₁..₅ */
        sub_1: sub_1 {
            compatible = "zmk,behavior-macro";
            #binding-cells = <0>;
            wait-ms = <40>;
            tap-ms = <40>;
            bindings =
                <&macro_release &kp RALT>,         /* neutralise AltGr */
                <&macro_release &kp LSHFT>,        /* neutralise Shift */
                <&macro_release &kp RSHFT>,
                <&macro_tap &kp RCTRL>,
                <&macro_tap &kp N8>, // FR N8 -> _ under
                <&macro_tap &kp KP_N1>;
        };

        sub_2: sub_2 {
            compatible = "zmk,behavior-macro";
            #binding-cells = <0>;
            wait-ms = <40>;
            tap-ms = <40>;
            bindings =
                <&macro_release &kp RALT>,         /* neutralise AltGr */
                <&macro_release &kp LSHFT>,        /* neutralise Shift */
                <&macro_release &kp RSHFT>,
                <&macro_tap &kp RCTRL>,
                <&macro_tap &kp N8>, // FR N8 -> _ under
                <&macro_tap &kp KP_N2>;
        };

        sub_3: sub_3 {
            compatible = "zmk,behavior-macro";
            #binding-cells = <0>;
            wait-ms = <40>;
            tap-ms = <40>;
            bindings =
                <&macro_release &kp RALT>,         /* neutralise AltGr */
                <&macro_release &kp LSHFT>,        /* neutralise Shift */
                <&macro_release &kp RSHFT>,
                <&macro_tap &kp RCTRL>,
                <&macro_tap &kp N8>, // FR N8 -> _ under
                <&macro_tap &kp KP_N3>;
        };

        sub_4: sub_4 {
            compatible = "zmk,behavior-macro";
            #binding-cells = <0>;
            wait-ms = <40>;
            tap-ms = <40>;
            bindings =
                <&macro_release &kp RALT>,         /* neutralise AltGr */
                <&macro_release &kp LSHFT>,        /* neutralise Shift */
                <&macro_release &kp RSHFT>,
                <&macro_tap &kp RCTRL>,
                <&macro_tap &kp N8>, // FR N8 -> _ under
                <&macro_tap &kp KP_N4>;
        };

        sub_5: sub_5 {
            compatible = "zmk,behavior-macro";
            #binding-cells = <0>;
            wait-ms = <40>;
            tap-ms = <40>;
            bindings =
                <&macro_release &kp RALT>,         /* neutralise AltGr */
                <&macro_release &kp LSHFT>,        /* neutralise Shift */
                <&macro_release &kp RSHFT>,
                <&macro_tap &kp RCTRL>,
                <&macro_tap &kp N8>, // FR N8 -> _ under
                <&macro_tap &kp KP_N5>;
        };

        sub_6: sub_6 {
            compatible = "zmk,behavior-macro";
            #binding-cells = <0>;
            wait-ms = <40>;
            tap-ms = <40>;
            bindings =
                <&macro_release &kp RALT>,         /* neutralise AltGr */
                <&macro_release &kp LSHFT>,        /* neutralise Shift */
                <&macro_release &kp RSHFT>,
                <&macro_tap &kp RCTRL>,
                <&macro_tap &kp N8>,               // FR N8 -> _ under
                <&macro_tap &kp KP_N6>;
            label = "₆";
        };
        
        sub_7: sub_7 {
            compatible = "zmk,behavior-macro";
            #binding-cells = <0>;
            wait-ms = <40>;
            tap-ms = <40>;
            bindings =
                <&macro_release &kp RALT>,
                <&macro_release &kp LSHFT>,
                <&macro_release &kp RSHFT>,
                <&macro_tap &kp RCTRL>,
                <&macro_tap &kp N8>,
                <&macro_tap &kp KP_N7>;
            label = "₇";
        };
        
        sub_8: sub_8 {
            compatible = "zmk,behavior-macro";
            #binding-cells = <0>;
            wait-ms = <40>;
            tap-ms = <40>;
            bindings =
                <&macro_release &kp RALT>,
                <&macro_release &kp LSHFT>,
                <&macro_release &kp RSHFT>,
                <&macro_tap &kp RCTRL>,
                <&macro_tap &kp N8>,
                <&macro_tap &kp KP_N8>;
            label = "₈";
        };
        
        sub_9: sub_9 {
            compatible = "zmk,behavior-macro";
            #binding-cells = <0>;
            wait-ms = <40>;
            tap-ms = <40>;
            bindings =
                <&macro_release &kp RALT>,
                <&macro_release &kp LSHFT>,
                <&macro_release &kp RSHFT>,
                <&macro_tap &kp RCTRL>,
                <&macro_tap &kp N8>,
                <&macro_tap &kp KP_N9>;
            label = "₉";
        };
        
        sub_0: sub_0 {
            compatible = "zmk,behavior-macro";
            #binding-cells = <0>;
            wait-ms = <40>;
            tap-ms = <40>;
            bindings =
                <&macro_release &kp RALT>,
                <&macro_release &kp LSHFT>,
                <&macro_release &kp RSHFT>,
                <&macro_tap &kp RCTRL>,
                <&macro_tap &kp N8>,
                <&macro_tap &kp KP_N0>;
            label = "₀";
        };

        sup_1: sup_1 {
            compatible = "zmk,behavior-macro";
            #binding-cells = <0>;
            wait-ms = <40>;
            tap-ms = <40>;
            bindings =
                <&macro_release &kp RALT>,         /* neutralise AltGr */
                <&macro_release &kp LSHFT>,        /* neutralise Shift */
                <&macro_release &kp RSHFT>,
                <&macro_tap &kp RCTRL>,
                <&macro_tap &kp RA(N9)>,
                <&macro_tap &kp KP_N1>;
        };

        sup_2: sup_2 {
            compatible = "zmk,behavior-macro";
            #binding-cells = <0>;
            wait-ms = <40>;
            tap-ms = <40>;
            bindings =
                <&macro_release &kp RALT>,         /* neutralise AltGr */
                <&macro_release &kp LSHFT>,        /* neutralise Shift */
                <&macro_release &kp RSHFT>,
                <&macro_tap &kp RCTRL>,
                <&macro_tap &kp RA(N9)>,
                <&macro_tap &kp KP_N2>;
        };

        sup_3: sup_3 {
            compatible = "zmk,behavior-macro";
            #binding-cells = <0>;
            wait-ms = <40>;
            tap-ms = <40>;
            bindings =
                <&macro_release &kp RALT>,         /* neutralise AltGr */
                <&macro_release &kp LSHFT>,        /* neutralise Shift */
                <&macro_release &kp RSHFT>,
                <&macro_tap &kp RCTRL>,
                <&macro_tap &kp RA(N9)>,
                <&macro_tap &kp KP_N3>;
        };

        sup_4: sup_4 {
            compatible = "zmk,behavior-macro";
            #binding-cells = <0>;
            wait-ms = <40>;
            tap-ms = <40>;
            bindings =
                <&macro_release &kp RALT>,         /* neutralise AltGr */
                <&macro_release &kp LSHFT>,        /* neutralise Shift */
                <&macro_release &kp RSHFT>,
                <&macro_tap &kp RCTRL>,
                <&macro_tap &kp RA(N9)>,
                <&macro_tap &kp KP_N4>;
        };

        sup_5: sup_5 {
            compatible = "zmk,behavior-macro";
            #binding-cells = <0>;
            wait-ms = <40>;
            tap-ms = <40>;
            bindings =
                <&macro_release &kp RALT>,         /* neutralise AltGr */
                <&macro_release &kp LSHFT>,        /* neutralise Shift */
                <&macro_release &kp RSHFT>,
                <&macro_tap &kp RCTRL>,
                <&macro_tap &kp RA(N9)>,
                <&macro_tap &kp KP_N5>;
        };

        sup_6: sup_6 {
            compatible = "zmk,behavior-macro";
            #binding-cells = <0>;
            wait-ms = <40>;
            tap-ms = <40>;
            bindings =
                <&macro_release &kp RALT>,
                <&macro_release &kp LSHFT>,
                <&macro_release &kp RSHFT>,
                <&macro_tap &kp RCTRL>,
                <&macro_tap &kp RA(N9)>,           // ^ en FR = AltGr+9
                <&macro_tap &kp KP_N6>;
            label = "⁶";
        };
        
        sup_7: sup_7 {
            compatible = "zmk,behavior-macro";
            #binding-cells = <0>;
            wait-ms = <40>;
            tap-ms = <40>;
            bindings =
                <&macro_release &kp RALT>,
                <&macro_release &kp LSHFT>,
                <&macro_release &kp RSHFT>,
                <&macro_tap &kp RCTRL>,
                <&macro_tap &kp RA(N9)>,
                <&macro_tap &kp KP_N7>;
            label = "⁷";
        };
        
        sup_8: sup_8 {
            compatible = "zmk,behavior-macro";
            #binding-cells = <0>;
            wait-ms = <40>;
            tap-ms = <40>;
            bindings =
                <&macro_release &kp RALT>,
                <&macro_release &kp LSHFT>,
                <&macro_release &kp RSHFT>,
                <&macro_tap &kp RCTRL>,
                <&macro_tap &kp RA(N9)>,
                <&macro_tap &kp KP_N8>;
            label = "⁸";
        };
        
        sup_9: sup_9 {
            compatible = "zmk,behavior-macro";
            #binding-cells = <0>;
            wait-ms = <40>;
            tap-ms = <40>;
            bindings =
                <&macro_release &kp RALT>,
                <&macro_release &kp LSHFT>,
                <&macro_release &kp RSHFT>,
                <&macro_tap &kp RCTRL>,
                <&macro_tap &kp RA(N9)>,
                <&macro_tap &kp KP_N9>;
            label = "⁹";
        };
        
        sup_0: sup_0 {
            compatible = "zmk,behavior-macro";
            #binding-cells = <0>;
            wait-ms = <40>;
            tap-ms = <40>;
            bindings =
                <&macro_release &kp RALT>,
                <&macro_release &kp LSHFT>,
                <&macro_release &kp RSHFT>,
                <&macro_tap &kp RCTRL>,
                <&macro_tap &kp RA(N9)>,
                <&macro_tap &kp KP_N0>;
            label = "⁰";
        };

        /* ======================================================= *
         * MACROS pour la couche layer_accented                    *
         * ======================================================= */

        /* LH R2 C1 — '‰' via Compose : Compose + % + o */
        permille_compose: permille_compose {
            compatible = "zmk,behavior-macro";
            #binding-cells = <0>;
            wait-ms = <40>;
            tap-ms = <40>;
            bindings =
                <&macro_release &kp RALT>,
                <&macro_release &kp LSHFT>,
                <&macro_release &kp RSHFT>,
                <&macro_tap     &kp RCTRL>,    /* Compose */
                <&macro_press   &kp RSHFT>,    /* % */
                <&macro_tap     &kp SQT>,
                <&macro_release &kp RSHFT>,
                <&macro_tap     &kp O>;        /* o => ‰ */
            label = "‰";
        };

        // Pilcrow : ¶ (Compose + P + !)

        pilcrow_compose: pilcrow_compose {
            compatible = "zmk,behavior-macro";
            #binding-cells = <0>;
            wait-ms = <40>;
            tap-ms = <40>;
            bindings =
                <&macro_release &kp RALT>,
                <&macro_release &kp LSHFT>,
                <&macro_release &kp RSHFT>,
                <&macro_tap     &kp RCTRL>,    /* Compose */
                <&macro_tap     &kp P>,        /* P */
                <&macro_tap     &kp FSLH>;     /* ! => ¶ */
            label = "¶";
        };

        // ñ (n tilde) U+00F1
        // N tilde : ñ (~ + n)

        n_tilde: n_tilde {
            compatible = "zmk,behavior-macro";
            #binding-cells = <0>;
            bindings = 
                <&macro_tap &kp RA(LBKT)>,  /* ~  en FR */
                <&macro_tap &kp N>;         /* N => ñ */
            label = "ñ";
        };

        // • (bullet) U+2022
        // Bullet : • (Compose + . + =)

        bullet_compose: bullet_compose {
            compatible = "zmk,behavior-macro";
            #binding-cells = <0>;
            wait-ms = <40>;
            tap-ms = <40>;
            bindings =
                <&macro_tap &kp RCTRL>, /* Compose */
                <&macro_tap &kp LS(COMMA)>,     /* ; en FR */
                <&macro_tap &kp KP_EQUAL>;         /* => •    */
            label = "•";
        };

        /* =========================================================== *
         * MACROS dont il faut vérifier si elles sont encore utilisées *
         * =========================================================== */

        guillemotleft_compose: guillemotleft_compose {
            compatible = "zmk,behavior-macro";
            #binding-cells = <0>;
            wait-ms = <40>;
            tap-ms = <40>;
            bindings =
                <&macro_tap &kp RCTRL>,
                <&macro_tap &kp NON_US_BSLH>,
                <&macro_tap &kp NON_US_BSLH>;
        };

        guillemotright_compose: guillemotright_compose {
            compatible = "zmk,behavior-macro";
            #binding-cells = <0>;
            wait-ms = <40>;
            tap-ms = <40>;
            bindings =
                <&macro_tap &kp RCTRL>,
                <&macro_press &kp RSHFT>,
                <&macro_tap &kp NON_US_BSLH>,
                <&macro_tap &kp NON_US_BSLH>,
                <&macro_release &kp RSHFT>;
        };

        // LH R2 C4
        // Inférieur ou égal : ≤ (Compose + < + =)
        leq_compose: leq_compose {
            compatible = "zmk,behavior-macro";
            #binding-cells = <0>;
            wait-ms = <40>;
            tap-ms = <40>;
            bindings =
                <&macro_release &kp RALT>,         /* neutralise AltGr */
                <&macro_release &kp LSHFT>,        /* neutralise Shift */
                <&macro_release &kp RSHFT>,
                <&macro_tap     &kp RCTRL>,        /* Compose */
                <&macro_tap     &kp NON_US_BSLH>,  /* < sur FR */
                <&macro_tap     &kp EQUAL>;       /* = */
            label = "≤";
        };

        // LH R2 C3 — '>' direct (sans dead-key / sans dépendre des mods tenus)
        gt_literal: gt_literal {
            compatible = "zmk,behavior-macro";
            #binding-cells = <0>;
            wait-ms = <30>;
            tap-ms = <30>;
            bindings =
                <&macro_release &kp RALT>,          /* neutralise AltGr */
                <&macro_release &kp LSHFT>,         /* neutralise Shift */
                <&macro_release &kp RSHFT>,
                <&macro_press   &kp RSHFT>,         /* fabrique '>' = Shift + NON_US_BSLH */
                <&macro_tap     &kp NON_US_BSLH>,
                <&macro_release &kp RSHFT>;
          label = ">";
        };

        // LH R2 C3 — '≥' via Compose : Compose + '>' + '='
        geq_compose: geq_compose {
            compatible = "zmk,behavior-macro";
            #binding-cells = <0>;
            wait-ms = <40>;
            tap-ms = <40>;
            bindings =
                <&macro_release &kp RALT>,          /* neutralise AltGr */
                <&macro_release &kp LSHFT>,         /* neutralise Shift */
                <&macro_release &kp RSHFT>,
                <&macro_tap     &kp RCTRL>,         /* Compose */
                <&macro_press   &kp RSHFT>,         /* '>' = Shift + NON_US_BSLH */
                <&macro_tap     &kp NON_US_BSLH>,
                <&macro_release &kp RSHFT>,
                <&macro_tap     &kp EQUAL>;
          label = "≥";
        };


        // Tréma : ï (¨ + i)

        i_diae: i_diae {
            compatible = "zmk,behavior-macro";
            #binding-cells = <0>;
            bindings = <&kp LS(LBKT) &kp I>;
            label = "ï";
            wait-ms = <0>;
        };

        // Tréma : ü (¨ + u)

        u_diae: u_diae {
            compatible = "zmk,behavior-macro";
            #binding-cells = <0>;
            bindings = <&kp LS(LBKT) &kp U>;
            label = "ü";
            wait-ms = <0>;
        };

        // Tréma : ë (¨ + e)

        e_diae: e_diae {
            compatible = "zmk,behavior-macro";
            #binding-cells = <0>;
            bindings = <&kp LS(LBKT) &kp E>;
            label = "ë";
            wait-ms = <0>;
        };

        // Tréma : ä (¨ + a)

        a_diae: a_diae {
            compatible = "zmk,behavior-macro";
            #binding-cells = <0>;
            bindings = <&kp LS(LBKT) &kp Q>;
            label = "ä";
            wait-ms = <0>;
        };

        // Tréma : ö (¨ + o)

        o_diae: o_diae {
            compatible = "zmk,behavior-macro";
            #binding-cells = <0>;
            bindings = <&kp LS(LBKT) &kp O>;
            label = "ö";
            wait-ms = <0>;
        };

        // Tréma : ẍ (¨ + x) - rare

        x_diae: x_diae {
            compatible = "zmk,behavior-macro";
            #binding-cells = <0>;
            bindings = <&kp LS(LBKT) &kp X>;
            label = "ẍ";
            wait-ms = <0>;
        };

        // Tréma : ẅ (¨ + w) - rare

        w_diae: w_diae {
            compatible = "zmk,behavior-macro";
            #binding-cells = <0>;
            bindings = <&kp LS(LBKT) &kp Z>;
            label = "ẅ";
            wait-ms = <0>;
        };

        // Tréma : ÿ (¨ + y)

        y_diae: y_diae {
            compatible = "zmk,behavior-macro";
            #binding-cells = <0>;
            bindings = <&kp LS(LBKT) &kp Y>;
            label = "ÿ";
            wait-ms = <0>;
        };

        // Tréma : ẗ (¨ + t) - rare

        t_diae: t_diae {
            compatible = "zmk,behavior-macro";
            #binding-cells = <0>;
            bindings = <&kp LS(LBKT) &kp T>;
            label = "ẗ";
            wait-ms = <0>;
        };

        // Tréma : ḧ (¨ + h) - rare

        h_diae: h_diae {
            compatible = "zmk,behavior-macro";
            #binding-cells = <0>;
            bindings = <&kp LS(LBKT) &kp H>;
            label = "ḧ";
            wait-ms = <0>;
        };

        // Caractère spécial : µ (micro/mu)

        mu: mu {
            compatible = "zmk,behavior-macro";
            #binding-cells = <0>;
            bindings = <&kp LS(BSLH)>;
            label = "µ";
        };

        // … (ellipsis) U+2026
        // Ellipsis : … (Compose + . + .)

        ellipsis_compose: ellipsis_compose {
            compatible = "zmk,behavior-macro";
            #binding-cells = <0>;
            wait-ms = <30>;
            tap-ms = <40>;
            bindings = <&kp RCTRL &kp KP_DOT &kp KP_DOT>;
            label = "…";
        };

        // ‑ (tiret insécable) U+2011
        // Tiret insécable : ‑ (Compose + - + , + -)

        nbsp_hyphen_compose: nbsp_hyphen_compose {
            compatible = "zmk,behavior-macro";
            #binding-cells = <0>;
            bindings = <&kp RCTRL &kp KP_MINUS &kp COMMA &kp KP_MINUS>;
            label = "‑";
        };

        // – (en dash) U+2013
        // En dash : – (Compose + - + -)

        en_dash_compose: en_dash_compose {
            compatible = "zmk,behavior-macro";
            #binding-cells = <0>;
            wait-ms = <30>;
            tap-ms = <40>;
            bindings = <&kp RCTRL &kp KP_MINUS &kp KP_MINUS>;
            label = "–";
        };

        // — (em dash) U+2014
        // Em dash : — (Compose + - + - + -)

        em_dash_compose: em_dash_compose {
            compatible = "zmk,behavior-macro";
            #binding-cells = <0>;
            wait-ms = <30>;
            tap-ms = <40>;
            bindings = <&kp RCTRL &kp KP_MINUS &kp KP_MINUS &kp KP_MINUS>;
            label = "—";
        };






        // · (middle dot) U+00B7
        // Middle dot : · (Compose + . + ^)

        middot_compose: middot_compose {
            compatible = "zmk,behavior-macro";
            #binding-cells = <0>;
            bindings = <&kp RCTRL &kp DOT &kp LBKT>;  // ^ = LBKT en FR
            label = "·";
        };

        // « (guillemet ouvrant) U+00AB
        // Guillemet ouvrant : « (Compose + < + <)

        guil_open_compose: guil_open_compose {
            compatible = "zmk,behavior-macro";
            #binding-cells = <0>;
            wait-ms = <30>;
            tap-ms = <40>;
            bindings = <&kp RCTRL &kp LS(COMMA) &kp LS(COMMA)>;  // < = Shift+,
            label = "«";
        };

        // » (guillemet fermant) U+00BB
        // Guillemet fermant : » (Compose + > + >)

        guil_close_compose: guil_close_compose {
            compatible = "zmk,behavior-macro";
            #binding-cells = <0>;
            wait-ms = <30>;
            tap-ms = <40>;
            bindings = <&kp RCTRL &kp LS(DOT) &kp LS(DOT)>;  // > = Shift+.
            label = "»";
        };



        // Alpha : α (Compose + * + a)

        alpha: alpha {
            compatible = "zmk,behavior-macro";
            #binding-cells = <0>;
            bindings = <&kp RCTRL &kp RBKT &kp Q>;  // A en FR = Q
            label = "α";
        };

        // Beta : β (Compose + * + b)

        beta: beta {
            compatible = "zmk,behavior-macro";
            #binding-cells = <0>;
            bindings = <&kp RCTRL &kp RBKT &kp B>;
            label = "β";
        };

        // Gamma : γ (Compose + * + g)

        gamma: gamma {
            compatible = "zmk,behavior-macro";
            #binding-cells = <0>;
            bindings = <&kp RCTRL &kp RBKT &kp G>;
            label = "γ";
        };

        // Delta : δ (Compose + * + d)

        delta: delta {
            compatible = "zmk,behavior-macro";
            #binding-cells = <0>;
            bindings = <&kp RCTRL &kp RBKT &kp D>;
            label = "δ";
        };

        // Epsilon : ε (Compose + * + e)

        epsilon: epsilon {
            compatible = "zmk,behavior-macro";
            #binding-cells = <0>;
            bindings = <&kp RCTRL &kp RBKT &kp E>;
            label = "ε";
        };

        // Zeta : ζ (Compose + * + z)

        zeta: zeta {
            compatible = "zmk,behavior-macro";
            #binding-cells = <0>;
            bindings = <&kp RCTRL &kp RBKT &kp Z>;  // Z en FR = W, mais pour zeta c'est la lettre latine z qui correspond
            label = "ζ";
        };

        // Eta : η (Compose + * + y)

        eta: eta {
            compatible = "zmk,behavior-macro";
            #binding-cells = <0>;
            bindings = <&kp RCTRL &kp RBKT &kp Y>;
            label = "η";
        };

        // Theta : θ (Compose + * + h)

        theta: theta {
            compatible = "zmk,behavior-macro";
            #binding-cells = <0>;
            bindings = <&kp RCTRL &kp RBKT &kp H>;
            label = "θ";
        };

        // Iota : ι (Compose + * + i)

        iota: iota {
            compatible = "zmk,behavior-macro";
            #binding-cells = <0>;
            bindings = <&kp RCTRL &kp RBKT &kp I>;
            label = "ι";
        };

        // Kappa : κ (Compose + * + k)

        kappa: kappa {
            compatible = "zmk,behavior-macro";
            #binding-cells = <0>;
            bindings = <&kp RCTRL &kp RBKT &kp K>;
            label = "κ";
        };

        // Lambda : λ (Compose + * + l)

        lambda: lambda {
            compatible = "zmk,behavior-macro";
            #binding-cells = <0>;
            bindings = <&kp RCTRL &kp RBKT &kp L>;
            label = "λ";
        };

        // Mu : μ (Compose + m + u)

        mu_greek: mu_greek {
            compatible = "zmk,behavior-macro";
            #binding-cells = <0>;
            bindings = <&kp RCTRL &kp RBKT &kp SEMICOLON>;  // M en FR = SEMICOLON (touche M physique)
            label = "μ";
        };

        // Nu : ν (Compose + * + n)

        nu: nu {
            compatible = "zmk,behavior-macro";
            #binding-cells = <0>;
            bindings = <&kp RCTRL &kp RBKT &kp N>;
            label = "ν";
        };

        // Xi : ξ (Compose + * + j)

        xi: xi {
            compatible = "zmk,behavior-macro";
            #binding-cells = <0>;
            bindings = <&kp RCTRL &kp RBKT &kp J>;
            label = "ξ";
        };

        // Omicron : ο (Compose + * + o)

        omicron: omicron {
            compatible = "zmk,behavior-macro";
            #binding-cells = <0>;
            bindings = <&kp RCTRL &kp RBKT &kp O>;
            label = "ο";
        };

        // Pi : π (Compose + * + p)

        pi: pi {
            compatible = "zmk,behavior-macro";
            #binding-cells = <0>;
            bindings = <&kp RCTRL &kp RBKT &kp P>;
            label = "π";
        };

        // Rho : ρ (Compose + * + r)

        rho: rho {
            compatible = "zmk,behavior-macro";
            #binding-cells = <0>;
            bindings = <&kp RCTRL &kp RBKT &kp R>;
            label = "ρ";
        };

        // Sigma : σ (Compose + * + s)

        sigma: sigma {
            compatible = "zmk,behavior-macro";
            #binding-cells = <0>;
            bindings = <&kp RCTRL &kp RBKT &kp S>;
            label = "σ";
        };

        // Tau : τ (Compose + * + t)

        tau: tau {
            compatible = "zmk,behavior-macro";
            #binding-cells = <0>;
            bindings = <&kp RCTRL &kp RBKT &kp T>;
            label = "τ";
        };

        // Upsilon : υ (Compose + * + u)

        upsilon: upsilon {
            compatible = "zmk,behavior-macro";
            #binding-cells = <0>;
            bindings = <&kp RCTRL &kp RBKT &kp U>;
            label = "υ";
        };

        // Phi : φ (Compose + * + f)

        phi: phi {
            compatible = "zmk,behavior-macro";
            #binding-cells = <0>;
            bindings = <&kp RCTRL &kp RBKT &kp F>;
            label = "φ";
        };

        // Chi : χ (Compose + * + x)

        chi: chi {
            compatible = "zmk,behavior-macro";
            #binding-cells = <0>;
            bindings = <&kp RCTRL &kp RBKT &kp X>;
            label = "χ";
        };

        // Psi : ψ (Compose + * + q)

        psi: psi {
            compatible = "zmk,behavior-macro";
            #binding-cells = <0>;
            bindings = <&kp RCTRL &kp RBKT &kp A>;  // Q en FR = A
            label = "ψ";
        };

        // Omega : ω (Compose + * + w)

        omega: omega {
            compatible = "zmk,behavior-macro";
            #binding-cells = <0>;
            bindings = <&kp RCTRL &kp RBKT &kp Z>;  // W en FR = Z
            label = "ω";
        };
    };

    keymap {
        compatible = "zmk,keymap";

        layer_Base {
            bindings = <
&kp ESC           &lhr1c5        &lhr1c4        &lhr1c3        &lhr1c2        &lhr1c1                                                                                       &rhr1c1     &rhr1c2         &rhr1c3    &rhr1c4      &rhr1c5    &kp BACKSPACE
&kp TAB           &lhr2c5_altgr  &lhr2c4_altgr  &lhr2c3_altgr  &lhr2c2_altgr  &lhr2c1_altgr                                                                                 &rhr2c1     &rhr2c2         &rhr2c3    &rhr2c4      &rhr2c5    &kp DELETE
&kp LEFT_SHIFT    &lhr3c5        &lhr3c4        &lhr3c3        &lhr3c2        &lhr3c1                                                                                       &rhr3c1     &rhr3c2         &rhr3c3    &rhr3c4      &rhr3c5    &kp RIGHT_SHIFT
&kp LEFT_CONTROL  &lhr4c5        &lhr4c4        &lhr4c3        &lhr4c2        &lhr4c1                                                                                       &rhr4c1     &rhr4c2         &rhr4c3    &rhr4c4      &rhr4c5    &keypad_td
                                 &magic 3 0     &lhr5c3        &lhr5c2                                                                                                                  &symbol_nav_td  &kp NON_US_BSLH  &kp LS(NON_US_BSLH)
                                                                                             &kp LEFT_ALT  &kp SPACE  &kp LEFT_GUI  &kp RIGHT_GUI  &kp SPACE  &mt RALT RET
            >;
        };

        layer_Keypad {
            bindings = <
&none                 &kp F1     &kp F2     &kp F3     &kp F4     &kp F5                                                                                     &kp F6     &kp F7     &kp F8      &kp F9        &kp F10          &kp F11
&trans                &none      &kp HOME   &kp UP     &kp END    &kp PG_UP                                                                                  &kp KP_N7  &kp KP_N8  &kp KP_N9   &kp KP_MINUS  &kp KP_SLASH     &kp F12
&trans                &kp LC(Y)  &kp LEFT   &kp DOWN   &kp RIGHT  &kp PG_DN                                                                                  &kp KP_N4  &kp KP_N5  &kp KP_N6   &kp KP_PLUS   &kp KP_MULTIPLY  &kp KP_NUM
&magic LAYER_Magic 0  &kp LC(Z)  &kp LC(X)  &kp LC(C)  &kp LC(V)  &kp LS(LC(V))                                                                              &kp KP_N1  &kp KP_N2  &kp KP_N3   &kp KP_ENTER  &kp EQUAL        &to LAYER_Base
                                 &none      &trans     &trans                                                                                                           &kp KP_N0  &kp KP_DOT  &kp BSPC
                                                                                 &mo LAYER_SymbolNav  &trans  &trans  &trans  &kp KP_COMMA  &mt RALT RETURN
            >;
        };

        layer_SymbolNav {
            bindings = <
&kp INS               &kp F1    &kp F2     &kp F3    &kp F4     &kp F5                                                             &kp F6    &kp F7    &kp F8           &kp F9       &kp F10          &kp F11
&kp SLCK              &kp EXCL  &kp HOME   &kp UP    &kp END    &kp PG_UP                                                          &kp LPAR  &kp RPAR  &kp UP           &kp PRCNT    &kp K_APP        &kp F12
&kp CAPS              &kp AT    &kp LEFT   &kp DOWN  &kp RIGHT  &kp PG_DN                                                          &kp DLLR  &kp LEFT  &kp DOWN         &kp RIGHT    &kp PAUSE_BREAK  &kp PSCRN
&magic LAYER_Magic 0  &kp HASH  &kp LBKT   &kp RBKT  &kp LBRC   &kp RBRC                                                           &kp AMPS  &kp STAR  &kp UNDER        &kp PLUS     &kp LSHFT        &kp LCTRL
                                &kp CARET  &trans    &trans                                                                                  &trans    &kp LC(LS(TAB))  &kp LC(TAB)
                                                                           &to LAYER_Base  &trans  &trans  &trans  &trans  &trans
            >;
        };

        layer_Magic {
            bindings = <
&bt BT_CLR   &kp C_BRI_DN     &kp C_BRI_UP     &kp C_PREV       &kp C_NEXT       &kp C_PP                                                   &kp C_MUTE  &kp C_VOL_DN  &kp C_VOL_UP  &none  &none  &bt BT_CLR_ALL
&bootloader  &rgb_ug RGB_SPI  &rgb_ug RGB_SAI  &rgb_ug RGB_HUI  &rgb_ug RGB_BRI  &rgb_ug RGB_TOG                                            &none       &none         &none         &none  &none  &bootloader
&sys_reset   &rgb_ug RGB_SPD  &rgb_ug RGB_SAD  &rgb_ug RGB_HUD  &rgb_ug RGB_BRD  &rgb_ug RGB_EFF                                            &none       &none         &none         &none  &none  &sys_reset
&none        &none            &bt_0            &bt_1            &bt_2            &bt_3                                                      &none       &none         &none         &none  &none  &to LAYER_Factory
                              &out OUT_USB     &none            &none                                                                                   &none         &none         &none
                                                                                                  &none  &none  &none  &none  &none  &none
            >;
        };

        layer_Factory {
            bindings = <
&kp N0  &kp N4  &kp N8  &kp N3  &kp N8  &kp N3                                                  &kp N3  &kp N8  &kp N3  &kp N8  &kp N4  &kp N0
&kp N1  &kp N5  &kp N9  &kp N4  &kp N9  &kp N4                                                  &kp N4  &kp N9  &kp N4  &kp N9  &kp N5  &kp N1
&kp N2  &kp N6  &kp N0  &kp N5  &kp N0  &kp N5                                                  &kp N5  &kp N0  &kp N5  &kp N0  &kp N6  &kp N2
&kp N3  &kp N7  &kp N1  &kp N6  &kp N1  &kp N6                                                  &kp N6  &kp N1  &kp N6  &kp N1  &kp N7  &kp N3
                &kp N2  &kp N7  &kp N2                                                                  &kp N2  &kp N7  &kp N2
                                                &kp N7  &kp N8  &kp N9  &kp N9  &kp N8  &kp N7
            >;
        };

        layer_Accented {
            bindings = <
&trans  &lhr1c5_accented  &lhr1c4_accented  &lhr1c3_accented  &lhr1c2_accented  &lhr1c1_accented                                      &none              &none        &rhr1c3_accented  &rhr1c4_accented  &rhr1c5_accented  &trans
&trans  &kp RA(W)         &kp N9     &kp RA(O)  &kp RA(P)         &none                                                             &none              &kp LS(BSLH) &kp N8        &rhr2c4_accented  &kp RA(SQT)     &trans
&trans  &kp N0            &kp N2     &kp N7     &kp RA(R)         &n_tilde                                                          &kp N5             &kp MINUS    &kp RA(I)     &kp RA(K)         &kp SQT         &trans
&trans  &kp RA(A)         &kp RA(S)  &lhr4c3_accented  &kp LS(RA(N5))    &kp LS(RA(N4))                                               &kp LS(RA(M))      &none        &sl 7         &rhr4c4_accented  &none           &trans
                          &trans     &trans     &trans                                                                                                 &trans       &trans        &trans
                                                                                    &trans  &trans  &trans  &trans  &trans  &trans
            >;
        };

        layer_Diae_Supplement {
            bindings = <
&trans  &trans   &trans   &trans   &trans  &trans                                                   &trans  &trans   &trans   &trans   &trans   &trans
&trans  &trans   &trans   &o_diae  &trans  &w_diae                                                  &trans  &trans   &trans   &trans   &y_diae  &trans
&trans  &a_diae  &trans   &e_diae  &trans  &trans                                                   &trans  &trans   &t_diae  &i_diae  &u_diae  &trans
&trans  &trans   &x_diae  &trans   &trans  &trans                                                   &trans  &h_diae  &trans   &trans   &trans   &trans
                 &trans   &trans   &trans                                                                   &trans   &trans   &trans
                                                    &trans  &trans  &trans  &trans  &trans  &trans
            >;
        };

        layer_Greek_Symbols {
            bindings = <
&trans  &trans  &trans  &trans  &trans  &trans                                                  &trans  &trans        &trans     &trans  &trans  &trans
&trans  &trans  &trans  &trans  &trans  &omega                                                  &trans  &kp LS(BSLH)  &mu_greek  &trans  &psi    &trans
&trans  &trans  &trans  &trans  &trans  &trans                                                  &trans  &trans        &trans     &trans  &trans  &trans
&trans  &trans  &trans  &trans  &trans  &trans                                                  &trans  &trans        &trans     &trans  &trans  &trans
                &trans  &trans  &trans                                                                  &trans        &trans     &trans
                                                &trans  &trans  &trans  &trans  &trans  &trans
            >;
        };
    };
};

&cirque_rh_listener {
    input-processors = <&zip_xy_scaler 3 1>;

    layer_2 {
        layers = <2>;
        input-processors = <&zip_xy_scaler 9 1>;
    };
};

&cirque_lh_listener {
    input-processors =
        <&zip_xy_to_scroll_mapper>,
        <&zip_xy_scaler 1 8>,
        <&zip_click_to_right_click_mapper>;

    layer_4 {
        layers = <4>;
        input-processors = <&zip_xy_scaler 3 1>;
    };
};
